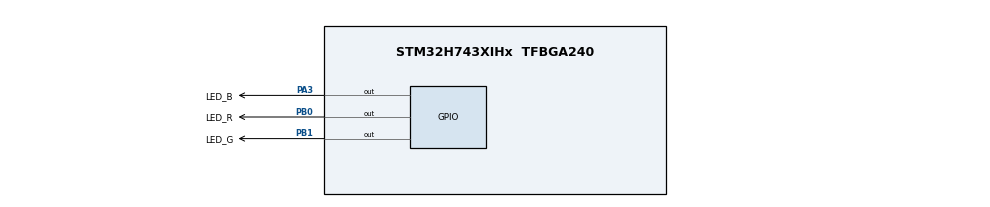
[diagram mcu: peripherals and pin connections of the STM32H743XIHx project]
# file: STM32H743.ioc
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Mcu.Family=STM32H7
Mcu.Name=STM32H743XIHx
Mcu.Package=TFBGA240
NVIC.PriorityGroup=NVIC_PRIORITYGROUP_4
PA3.GPIO_Label=LED_B
PA3.GPIO_PuPd=GPIO_PULLUP
PA3.GPIO_Speed=GPIO_SPEED_FREQ_VERY_HIGH
PA3.Signal=GPIO_Output
PB0.GPIO_Label=LED_R
PB0.GPIO_PuPd=GPIO_PULLUP
PB0.GPIO_Speed=GPIO_SPEED_FREQ_VERY_HIGH
PB0.Signal=GPIO_Output
PB1.GPIO_Label=LED_G
PB1.GPIO_PuPd=GPIO_PULLUP
PB1.GPIO_Speed=GPIO_SPEED_FREQ_VERY_HIGH
PB1.Signal=GPIO_Output
ProjectManager.HeapSize=0x200
ProjectManager.StackSize=0x400
ProjectManager.TargetToolchain=STM32CubeIDE
RCC.ADCFreq_Value=129000000
RCC.APB1Freq_Value=32000000
RCC.APB2Freq_Value=32000000
RCC.APB3Freq_Value=32000000
RCC.APB4Freq_Value=32000000
RCC.CortexFreq_Value=64000000
RCC.D1PPRE=RCC_APB3_DIV2
RCC.D2PPRE1=RCC_APB1_DIV2
RCC.D2PPRE2=RCC_APB2_DIV2
RCC.D3PPRE=RCC_APB4_DIV2
RCC.DIVM1=4
RCC.DIVN1=30
RCC.HCLKFreq_Value=64000000
RCC.SYSCLKFreq_VALUE=64000000
RCC.USBFreq_Value=240000000
board=custom

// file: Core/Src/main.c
/* USER CODE BEGIN Header */
/**
  ******************************************************************************
  * @file           : main.c
  * @brief          : Main program body
  ******************************************************************************
  * @attention
  *
  * Copyright (c) 2024 STMicroelectronics.
  * All rights reserved.
  *
  * This software is licensed under terms that can be found in the LICENSE file
  * in the root directory of this software component.
  * If no LICENSE file comes with this software, it is provided AS-IS.
  *
  ******************************************************************************
  */
/* USER CODE END Header */

#include "Mymain.h"

void SystemClock_Config(void);

int main(void)
{

  /* MCU Configuration--------------------------------------------------------*/

  /* Reset of all peripherals, Initializes the Flash interface and the Systick. */
  HAL_Init();

  /* Configure the system clock */
  SystemClock_Config();

  /* Initialize all configured peripherals */
  MX_GPIO_Init();
  /* USER CODE BEGIN 2 */

    Mymain();
  /* USER CODE END 2 */

  /* Infinite loop */
  while (1)
  {

  }
}

void SystemClock_Config(void)
{
  RCC_OscInitTypeDef RCC_OscInitStruct = {0};
  RCC_ClkInitTypeDef RCC_ClkInitStruct = {0};

  /** Supply configuration update enable
  */
  HAL_PWREx_ConfigSupply(PWR_LDO_SUPPLY);

  /** Configure the main internal regulator output voltage
  */
  __HAL_PWR_VOLTAGESCALING_CONFIG(PWR_REGULATOR_VOLTAGE_SCALE3);

  while(!__HAL_PWR_GET_FLAG(PWR_FLAG_VOSRDY)) {}

  /** Initializes the RCC Oscillators according to the specified parameters
  * in the RCC_OscInitTypeDef structure.
  */
  RCC_OscInitStruct.OscillatorType = RCC_OSCILLATORTYPE_HSI;
  RCC_OscInitStruct.HSIState = RCC_HSI_DIV1;
  RCC_OscInitStruct.HSICalibrationValue = RCC_HSICALIBRATION_DEFAULT;
  RCC_OscInitStruct.PLL.PLLState = RCC_PLL_NONE;
  if (HAL_RCC_OscConfig(&RCC_OscInitStruct) != HAL_OK)
  {
    Error_Handler();
  }

  /** Initializes the CPU, AHB and APB buses clocks
  */
  RCC_ClkInitStruct.ClockType = RCC_CLOCKTYPE_HCLK|RCC_CLOCKTYPE_SYSCLK
                              |RCC_CLOCKTYPE_PCLK1|RCC_CLOCKTYPE_PCLK2
                              |RCC_CLOCKTYPE_D3PCLK1|RCC_CLOCKTYPE_D1PCLK1;
  RCC_ClkInitStruct.SYSCLKSource = RCC_SYSCLKSOURCE_HSI;
  RCC_ClkInitStruct.SYSCLKDivider = RCC_SYSCLK_DIV1;
  RCC_ClkInitStruct.AHBCLKDivider = RCC_HCLK_DIV1;
  RCC_ClkInitStruct.APB3CLKDivider = RCC_APB3_DIV2;
  RCC_ClkInitStruct.APB1CLKDivider = RCC_APB1_DIV2;
  RCC_ClkInitStruct.APB2CLKDivider = RCC_APB2_DIV2;
  RCC_ClkInitStruct.APB4CLKDivider = RCC_APB4_DIV2;

  if (HAL_RCC_ClockConfig(&RCC_ClkInitStruct, FLASH_LATENCY_1) != HAL_OK)
  {
    Error_Handler();
  }
}

void Error_Handler(void)
{
  __disable_irq();
  while (1)
  {
  }
}
